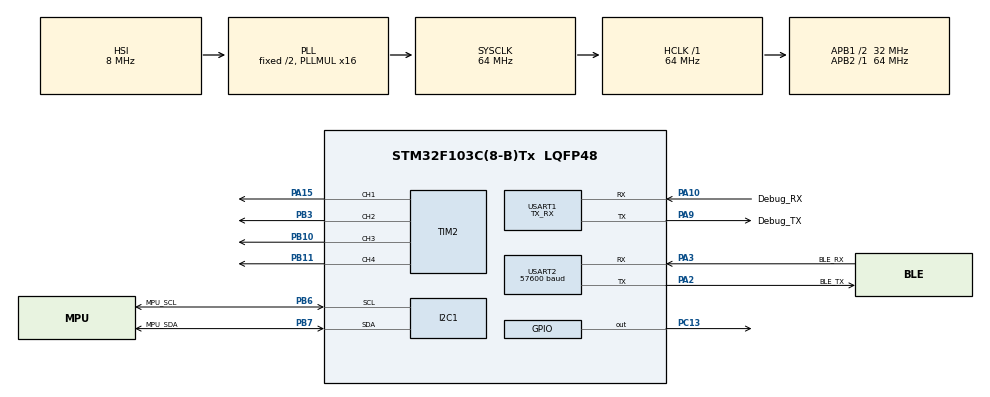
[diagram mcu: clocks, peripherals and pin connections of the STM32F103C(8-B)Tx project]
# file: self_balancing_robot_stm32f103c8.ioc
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Mcu.Family=STM32F1
Mcu.Name=STM32F103C(8-B)Tx
Mcu.Package=LQFP48
NVIC.I2C1_EV_IRQn=true\:0\:0\:false\:false\:true\:true
NVIC.PriorityGroup=NVIC_PRIORITYGROUP_4
NVIC.TIM1_UP_IRQn=true\:0\:0\:false\:false\:true\:true
NVIC.USART1_IRQn=true\:0\:0\:false\:false\:true\:true
PA10.GPIO_Label=Debug_RX
PA10.Mode=Asynchronous
PA10.Signal=USART1_RX
PA13.Mode=Serial_Wire
PA13.Signal=SYS_JTMS-SWDIO
PA14.Mode=Serial_Wire
PA14.Signal=SYS_JTCK-SWCLK
PA15.Signal=S_TIM2_CH1_ETR
PA2.GPIO_Label=BLE_TX
PA2.Mode=Asynchronous
PA2.Signal=USART2_TX
PA3.GPIO_Label=BLE_RX
PA3.Mode=Asynchronous
PA3.Signal=USART2_RX
PA9.GPIO_Label=Debug_TX
PA9.Mode=Asynchronous
PA9.Signal=USART1_TX
PB10.Signal=S_TIM2_CH3
PB11.Signal=S_TIM2_CH4
PB3.Signal=S_TIM2_CH2
PB6.GPIO_Label=MPU_SCL
PB6.Mode=I2C
PB6.Signal=I2C1_SCL
PB7.GPIO_Label=MPU_SDA
PB7.Mode=I2C
PB7.Signal=I2C1_SDA
PC13-TAMPER-RTC.Signal=GPIO_Output
ProjectManager.HeapSize=0x200
ProjectManager.StackSize=0x400
ProjectManager.TargetToolchain=MDK-ARM V5
RCC.AHBFreq_Value=64000000
RCC.APB1CLKDivider=RCC_HCLK_DIV2
RCC.APB1Freq_Value=32000000
RCC.APB1TimFreq_Value=64000000
RCC.APB2Freq_Value=64000000
RCC.APB2TimFreq_Value=64000000
RCC.HCLKFreq_Value=64000000
RCC.PLLMUL=RCC_PLL_MUL16
RCC.SYSCLKFreq_VALUE=64000000
RCC.SYSCLKSource=RCC_SYSCLKSOURCE_PLLCLK
RCC.USBFreq_Value=64000000
SH.S_TIM2_CH1_ETR.0=TIM2_CH1,PWM Generation1 CH1
SH.S_TIM2_CH2.0=TIM2_CH2,PWM Generation2 CH2
SH.S_TIM2_CH3.0=TIM2_CH3,PWM Generation3 CH3
SH.S_TIM2_CH4.0=TIM2_CH4,PWM Generation4 CH4
TIM1.AutoReloadPreload=TIM_AUTORELOAD_PRELOAD_ENABLE
TIM1.Period=10
TIM1.Prescaler=64000
TIM1.TIM_MasterOutputTrigger=TIM_TRGO_RESET
TIM2.Channel-PWM\ Generation1\ CH1=TIM_CHANNEL_1
TIM2.Channel-PWM\ Generation2\ CH2=TIM_CHANNEL_2
TIM2.Channel-PWM\ Generation3\ CH3=TIM_CHANNEL_3
TIM2.Channel-PWM\ Generation4\ CH4=TIM_CHANNEL_4
USART1.Mode=MODE_TX_RX
USART1.VirtualMode=VM_ASYNC
USART2.BaudRate=57600
USART2.VirtualMode=VM_ASYNC
VP_TIM1_VS_ClockSourceINT.Mode=Internal
board=custom

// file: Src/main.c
/* USER CODE BEGIN Header */
/**
  ******************************************************************************
  * @file           : main.c
  * @brief          : Main program body
  ******************************************************************************
  ** This notice applies to any and all portions of this file
  * that are not between comment pairs USER CODE BEGIN and
  * USER CODE END. Other portions of this file, whether
  * inserted by the user or by software development tools
  * are owned by their respective copyright owners.
  *
  * COPYRIGHT(c) 2019 STMicroelectronics
  *
  * Redistribution and use in source and binary forms, with or without modification,
  * are permitted provided that the following conditions are met:
  *   1. Redistributions of source code must retain the above copyright notice,
  *      this list of conditions and the following disclaimer.
  *   2. Redistributions in binary form must reproduce the above copyright notice,
  *      this list of conditions and the following disclaimer in the documentation
  *      and/or other materials provided with the distribution.
  *   3. Neither the name of STMicroelectronics nor the names of its contributors
  *      may be used to endorse or promote products derived from this software
  *      without specific prior written permission.
  *
  * THIS SOFTWARE IS PROVIDED BY THE COPYRIGHT HOLDERS AND CONTRIBUTORS "AS IS"
  * AND ANY EXPRESS OR IMPLIED WARRANTIES, INCLUDING, BUT NOT LIMITED TO, THE
  * IMPLIED WARRANTIES OF MERCHANTABILITY AND FITNESS FOR A PARTICULAR PURPOSE ARE
  * DISCLAIMED. IN NO EVENT SHALL THE COPYRIGHT HOLDER OR CONTRIBUTORS BE LIABLE
  * FOR ANY DIRECT, INDIRECT, INCIDENTAL, SPECIAL, EXEMPLARY, OR CONSEQUENTIAL
  * DAMAGES (INCLUDING, BUT NOT LIMITED TO, PROCUREMENT OF SUBSTITUTE GOODS OR
  * SERVICES; LOSS OF USE, DATA, OR PROFITS; OR BUSINESS INTERRUPTION) HOWEVER
  * CAUSED AND ON ANY THEORY OF LIABILITY, WHETHER IN CONTRACT, STRICT LIABILITY,
  * OR TORT (INCLUDING NEGLIGENCE OR OTHERWISE) ARISING IN ANY WAY OUT OF THE USE
  * OF THIS SOFTWARE, EVEN IF ADVISED OF THE POSSIBILITY OF SUCH DAMAGE.
  *
  ******************************************************************************
  */
/* USER CODE END Header */

#include "main.h"
#include "i2c.h"
#include "tim.h"
#include "usart.h"
#include "gpio.h"

//#define USING_HAL

extern st_MPU6050_Data v_MPU6050_Data;

void SystemClock_Config(void);
void Initialize_MPU6050_StructValue(void);

int main(void)
{
  /* MCU Configuration--------------------------------------------------------*/

  /* Reset of all peripherals, Initializes the Flash interface and the Systick. */
  HAL_Init();

  /* Configure the system clock */
  SystemClock_Config();

  /* Initialize all configured peripherals */
  MX_TIM2_Init();
  MX_TIM1_Init();
	MX_USART1_UART_Init();
	HAL_UART_MspInit(&huart1);

#ifdef USING_HAL
  MX_GPIO_Init();
  MX_I2C1_Init();
	HAL_I2C_MspInit(&hi2c1);
	MX_USART2_UART_Init();
	HAL_UART_MspInit(&huart2);
#else
	GPIO_Init();
	I2C1_Init(&hi2c1);
	USART2_Init(&huart2);
#endif

  Initialize_MPU6050_StructValue();
  HAL_Delay(100);
  printf("ECE 6780 - Balancing Robot\n");
  MPU_Initialize();
  /* Infinite loop */
  /* USER CODE BEGIN WHILE */
  while (1)
  {
		MPU_mem_read(MPU6050_WHO_I_AM_ADDR);
		HAL_Delay(1000);
    /* USER CODE END WHILE */
  }
}

void SystemClock_Config(void)
{
  RCC_OscInitTypeDef RCC_OscInitStruct = {0};
  RCC_ClkInitTypeDef RCC_ClkInitStruct = {0};

  /**Initializes the CPU, AHB and APB busses clocks
  */
  RCC_OscInitStruct.OscillatorType = RCC_OSCILLATORTYPE_HSI;
  RCC_OscInitStruct.HSIState = RCC_HSI_ON;
  RCC_OscInitStruct.HSICalibrationValue = RCC_HSICALIBRATION_DEFAULT;
  RCC_OscInitStruct.PLL.PLLState = RCC_PLL_ON;
  RCC_OscInitStruct.PLL.PLLSource = RCC_PLLSOURCE_HSI_DIV2;
  RCC_OscInitStruct.PLL.PLLMUL = RCC_PLL_MUL16;
  if (HAL_RCC_OscConfig(&RCC_OscInitStruct) != HAL_OK)
  {
    Error_Handler();
  }
  /**Initializes the CPU, AHB and APB busses clocks
  */
  RCC_ClkInitStruct.ClockType = RCC_CLOCKTYPE_HCLK|RCC_CLOCKTYPE_SYSCLK
                              |RCC_CLOCKTYPE_PCLK1|RCC_CLOCKTYPE_PCLK2;
  RCC_ClkInitStruct.SYSCLKSource = RCC_SYSCLKSOURCE_PLLCLK;
  RCC_ClkInitStruct.AHBCLKDivider = RCC_SYSCLK_DIV1;
  RCC_ClkInitStruct.APB1CLKDivider = RCC_HCLK_DIV2;
  RCC_ClkInitStruct.APB2CLKDivider = RCC_HCLK_DIV1;

  if (HAL_RCC_ClockConfig(&RCC_ClkInitStruct, FLASH_LATENCY_2) != HAL_OK)
  {
    Error_Handler();
  }
}

void Error_Handler()
{
	printf("Error Found\n");
}

void Initialize_MPU6050_StructValue()
{
  v_MPU6050_Data.accel_x = 0;
  v_MPU6050_Data.accel_y = 0;
  v_MPU6050_Data.accel_z = 0;
  v_MPU6050_Data.gyro_x = 0;
  v_MPU6050_Data.gyro_y = 0;
  v_MPU6050_Data.gyro_z = 0;
}
#ifdef __GNUC__
  /* With GCC/RAISONANCE, small printf (option LD Linker->Libraries->Small printf
     set to 'Yes') calls __io_putchar() */
  #define PUTCHAR_PROTOTYPE int __io_putchar(int ch)
#else
  #define PUTCHAR_PROTOTYPE int fputc(int ch, FILE *f)
#endif /* __GNUC__ */
/**
  * @brief  Retargets the C library printf function to the USART.
  * @param  None
  * @retval None
  */
PUTCHAR_PROTOTYPE
{
  /* Place your implementation of fputc here */
  /* e.g. write a character to the EVAL_COM1 and Loop until the end of transmission */
  HAL_UART_Transmit(&huart1, (uint8_t *)&ch, 1, 100);

  return ch;
}

/************************ (C) COPYRIGHT STMicroelectronics *****END OF FILE****/
